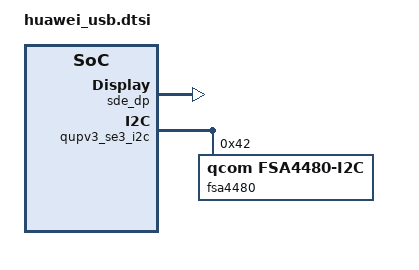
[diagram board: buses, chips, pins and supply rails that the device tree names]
&huawei_pd {
	src_vconn = <1>; /* vbatsys */
	src_vbus = <3>; /* pmic-8350b */
	otg_ocp_check_enable = <1>;
	cc_dynamic_protect = <2>;
	quirks_fix_flag = <1>;
};

&mdss_mdp {
	connectors = <&smmu_sde_unsec &smmu_sde_sec &sde_wb &sde_dsi &sde_rscc &sde_dp>;
};

&sde_dp{
	status = "ok";
	qcom,dp-aux-switch = <&fsa4480>;
};

&qupv3_se3_i2c {
	#address-cells = <1>;
	#size-cells = <0>;
	status = "ok";
	fsa4480: fsa4480@42 {
		compatible = "qcom,fsa4480-i2c";
		reg = <0x42>;
		status = "ok";
	};
};


